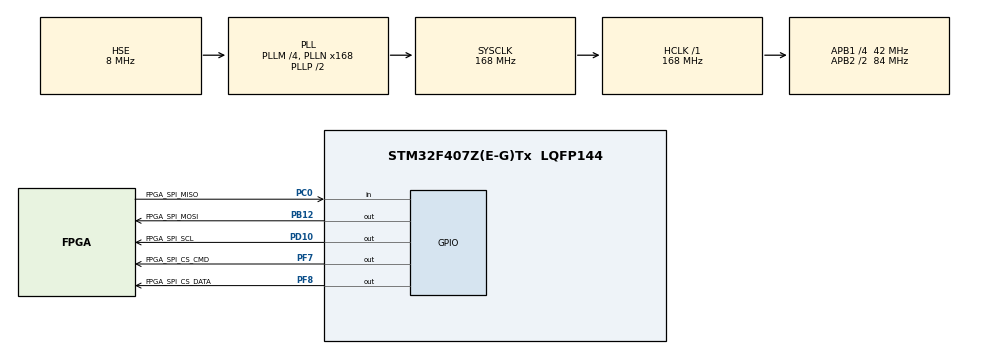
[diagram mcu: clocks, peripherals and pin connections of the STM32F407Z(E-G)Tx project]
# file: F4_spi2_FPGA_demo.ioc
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Mcu.Family=STM32F4
Mcu.Name=STM32F407Z(E-G)Tx
Mcu.Package=LQFP144
NVIC.PriorityGroup=NVIC_PRIORITYGROUP_4
PA13.Mode=Serial_Wire
PA13.Signal=SYS_JTMS-SWDIO
PA14.Mode=Serial_Wire
PA14.Signal=SYS_JTCK-SWCLK
PB12.GPIO_Label=FPGA_SPI_MOSI
PB12.GPIO_Speed=GPIO_SPEED_FREQ_VERY_HIGH
PB12.Signal=GPIO_Output
PC0.GPIO_Label=FPGA_SPI_MISO
PC0.Signal=GPIO_Input
PD10.GPIO_Label=FPGA_SPI_SCL
PD10.GPIO_Speed=GPIO_SPEED_FREQ_VERY_HIGH
PD10.Signal=GPIO_Output
PF7.GPIO_Label=FPGA_SPI_CS_CMD
PF7.GPIO_Speed=GPIO_SPEED_FREQ_VERY_HIGH
PF7.PinState=GPIO_PIN_SET
PF7.Signal=GPIO_Output
PF8.GPIO_Label=FPGA_SPI_CS_DATA
PF8.GPIO_Speed=GPIO_SPEED_FREQ_VERY_HIGH
PF8.PinState=GPIO_PIN_SET
PF8.Signal=GPIO_Output
PH0-OSC_IN.Mode=HSE-External-Oscillator
PH0-OSC_IN.Signal=RCC_OSC_IN
PH1-OSC_OUT.Mode=HSE-External-Oscillator
PH1-OSC_OUT.Signal=RCC_OSC_OUT
ProjectManager.HeapSize=0x200
ProjectManager.StackSize=0x400
ProjectManager.TargetToolchain=MDK-ARM V5.32
RCC.48MHZClocksFreq_Value=84000000
RCC.AHBFreq_Value=168000000
RCC.APB1CLKDivider=RCC_HCLK_DIV4
RCC.APB1Freq_Value=42000000
RCC.APB1TimFreq_Value=84000000
RCC.APB2CLKDivider=RCC_HCLK_DIV2
RCC.APB2Freq_Value=84000000
RCC.APB2TimFreq_Value=168000000
RCC.CortexFreq_Value=168000000
RCC.HCLKFreq_Value=168000000
RCC.HSE_VALUE=8000000
RCC.HSI_VALUE=16000000
RCC.LSE_VALUE=32768
RCC.PLLM=4
RCC.PLLN=168
RCC.PLLSourceVirtual=RCC_PLLSOURCE_HSE
RCC.SYSCLKFreq_VALUE=168000000
RCC.SYSCLKSource=RCC_SYSCLKSOURCE_PLLCLK
RCC.VCOOutputFreq_Value=336000000
TIM6.Prescaler=84-1
VP_TIM6_VS_ClockSourceINT.Mode=Enable_Timer
board=custom

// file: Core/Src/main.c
/* USER CODE BEGIN Header */
/**
  ******************************************************************************
  * @file           : main.c
  * @brief          : Main program body
  ******************************************************************************
  * @attention
  *
  * <h2><center>&copy; Copyright (c) 2021 STMicroelectronics.
  * All rights reserved.</center></h2>
  *
  * This software component is licensed by ST under BSD 3-Clause license,
  * the "License"; You may not use this file except in compliance with the
  * License. You may obtain a copy of the License at:
  *                        opensource.org/licenses/BSD-3-Clause
  *
  ******************************************************************************
  */
/* USER CODE END Header */
#include "main.h"

/* USER CODE BEGIN Includes */
#include "Drv_FPGA_SPI.h"
/* USER CODE END Includes */

TIM_HandleTypeDef htim6;

void SystemClock_Config(void);
static void MX_GPIO_Init(void);
static void MX_TIM6_Init(void);

int main(void)
{

  /* MCU Configuration--------------------------------------------------------*/

  /* Reset of all peripherals, Initializes the Flash interface and the Systick. */
  HAL_Init();

  /* Configure the system clock */
  SystemClock_Config();

  /* Initialize all configured peripherals */
  MX_GPIO_Init();
  MX_TIM6_Init();
  /* USER CODE BEGIN 2 */
  uint32_t i;
	uint32_t buf_send[8] = {0x11, 0x21, 0x32, 0x43, 0x54, 0x65, 0x76, 0x77};
	uint32_t buf_rece[8];
  // todo
		for(i = 0; i < 8; ++i)
		{
			FPGA_SPI_Send(8+i, buf_send[i]);
			HAL_Delay(50);
		}
		HAL_Delay(50);
		for(i = 0; i < 8; ++i)
		{
			buf_rece[i] = FPGA_SPI_Rece(i);
			HAL_Delay(50);
		}
		HAL_Delay(50);
  /* USER CODE END 2 */

  /* Infinite loop */
  /* USER CODE BEGIN WHILE */
  while (1)
  {
//		FPGA_SPI_Send_Cmd(5);

    /* USER CODE END WHILE */

  }
}

void SystemClock_Config(void)
{
  RCC_OscInitTypeDef RCC_OscInitStruct = {0};
  RCC_ClkInitTypeDef RCC_ClkInitStruct = {0};

  /** Configure the main internal regulator output voltage
  */
  __HAL_RCC_PWR_CLK_ENABLE();
  __HAL_PWR_VOLTAGESCALING_CONFIG(PWR_REGULATOR_VOLTAGE_SCALE1);
  /** Initializes the RCC Oscillators according to the specified parameters
  * in the RCC_OscInitTypeDef structure.
  */
  RCC_OscInitStruct.OscillatorType = RCC_OSCILLATORTYPE_HSE;
  RCC_OscInitStruct.HSEState = RCC_HSE_ON;
  RCC_OscInitStruct.PLL.PLLState = RCC_PLL_ON;
  RCC_OscInitStruct.PLL.PLLSource = RCC_PLLSOURCE_HSE;
  RCC_OscInitStruct.PLL.PLLM = 4;
  RCC_OscInitStruct.PLL.PLLN = 168;
  RCC_OscInitStruct.PLL.PLLP = RCC_PLLP_DIV2;
  RCC_OscInitStruct.PLL.PLLQ = 4;
  if (HAL_RCC_OscConfig(&RCC_OscInitStruct) != HAL_OK)
  {
    Error_Handler();
  }
  /** Initializes the CPU, AHB and APB buses clocks
  */
  RCC_ClkInitStruct.ClockType = RCC_CLOCKTYPE_HCLK|RCC_CLOCKTYPE_SYSCLK
                              |RCC_CLOCKTYPE_PCLK1|RCC_CLOCKTYPE_PCLK2;
  RCC_ClkInitStruct.SYSCLKSource = RCC_SYSCLKSOURCE_PLLCLK;
  RCC_ClkInitStruct.AHBCLKDivider = RCC_SYSCLK_DIV1;
  RCC_ClkInitStruct.APB1CLKDivider = RCC_HCLK_DIV4;
  RCC_ClkInitStruct.APB2CLKDivider = RCC_HCLK_DIV2;

  if (HAL_RCC_ClockConfig(&RCC_ClkInitStruct, FLASH_LATENCY_5) != HAL_OK)
  {
    Error_Handler();
  }
}

static void MX_TIM6_Init(void)
{

  TIM_MasterConfigTypeDef sMasterConfig = {0};

  htim6.Instance = TIM6;
  htim6.Init.Prescaler = 84-1;
  htim6.Init.CounterMode = TIM_COUNTERMODE_UP;
  htim6.Init.Period = 65535;
  htim6.Init.AutoReloadPreload = TIM_AUTORELOAD_PRELOAD_DISABLE;
  if (HAL_TIM_Base_Init(&htim6) != HAL_OK)
  {
    Error_Handler();
  }
  sMasterConfig.MasterOutputTrigger = TIM_TRGO_RESET;
  sMasterConfig.MasterSlaveMode = TIM_MASTERSLAVEMODE_DISABLE;
  if (HAL_TIMEx_MasterConfigSynchronization(&htim6, &sMasterConfig) != HAL_OK)
  {
    Error_Handler();
  }

}

static void MX_GPIO_Init(void)
{
  GPIO_InitTypeDef GPIO_InitStruct = {0};

  /* GPIO Ports Clock Enable */
  __HAL_RCC_GPIOE_CLK_ENABLE();
  __HAL_RCC_GPIOC_CLK_ENABLE();
  __HAL_RCC_GPIOF_CLK_ENABLE();
  __HAL_RCC_GPIOH_CLK_ENABLE();
  __HAL_RCC_GPIOA_CLK_ENABLE();
  __HAL_RCC_GPIOB_CLK_ENABLE();
  __HAL_RCC_GPIOG_CLK_ENABLE();
  __HAL_RCC_GPIOD_CLK_ENABLE();

  /*Configure GPIO pin Output Level */
  HAL_GPIO_WritePin(GPIOF, FPGA_SPI_CS_CMD_Pin|FPGA_SPI_CS_DATA_Pin, GPIO_PIN_SET);

  /*Configure GPIO pin Output Level */
  HAL_GPIO_WritePin(FPGA_SPI_MOSI_GPIO_Port, FPGA_SPI_MOSI_Pin, GPIO_PIN_RESET);

  /*Configure GPIO pin Output Level */
  HAL_GPIO_WritePin(FPGA_SPI_SCL_GPIO_Port, FPGA_SPI_SCL_Pin, GPIO_PIN_RESET);

  /*Configure GPIO pins : PE2 PE3 PE4 PE5
                           PE6 PE7 PE8 PE9
                           PE10 PE11 PE12 PE13
                           PE14 PE15 PE0 PE1 */
  GPIO_InitStruct.Pin = GPIO_PIN_2|GPIO_PIN_3|GPIO_PIN_4|GPIO_PIN_5
                          |GPIO_PIN_6|GPIO_PIN_7|GPIO_PIN_8|GPIO_PIN_9
                          |GPIO_PIN_10|GPIO_PIN_11|GPIO_PIN_12|GPIO_PIN_13
                          |GPIO_PIN_14|GPIO_PIN_15|GPIO_PIN_0|GPIO_PIN_1;
  GPIO_InitStruct.Mode = GPIO_MODE_ANALOG;
  GPIO_InitStruct.Pull = GPIO_NOPULL;
  HAL_GPIO_Init(GPIOE, &GPIO_InitStruct);

  /*Configure GPIO pins : PC13 PC14 PC15 PC1
                           PC2 PC3 PC4 PC5
                           PC6 PC7 PC8 PC9
                           PC10 PC11 PC12 */
  GPIO_InitStruct.Pin = GPIO_PIN_13|GPIO_PIN_14|GPIO_PIN_15|GPIO_PIN_1
                          |GPIO_PIN_2|GPIO_PIN_3|GPIO_PIN_4|GPIO_PIN_5
                          |GPIO_PIN_6|GPIO_PIN_7|GPIO_PIN_8|GPIO_PIN_9
                          |GPIO_PIN_10|GPIO_PIN_11|GPIO_PIN_12;
  GPIO_InitStruct.Mode = GPIO_MODE_ANALOG;
  GPIO_InitStruct.Pull = GPIO_NOPULL;
  HAL_GPIO_Init(GPIOC, &GPIO_InitStruct);

  /*Configure GPIO pins : PF0 PF1 PF2 PF3
                           PF4 PF5 PF6 PF9
                           PF10 PF11 PF12 PF13
                           PF14 PF15 */
  GPIO_InitStruct.Pin = GPIO_PIN_0|GPIO_PIN_1|GPIO_PIN_2|GPIO_PIN_3
                          |GPIO_PIN_4|GPIO_PIN_5|GPIO_PIN_6|GPIO_PIN_9
                          |GPIO_PIN_10|GPIO_PIN_11|GPIO_PIN_12|GPIO_PIN_13
                          |GPIO_PIN_14|GPIO_PIN_15;
  GPIO_InitStruct.Mode = GPIO_MODE_ANALOG;
  GPIO_InitStruct.Pull = GPIO_NOPULL;
  HAL_GPIO_Init(GPIOF, &GPIO_InitStruct);

  /*Configure GPIO pins : FPGA_SPI_CS_CMD_Pin FPGA_SPI_CS_DATA_Pin */
  GPIO_InitStruct.Pin = FPGA_SPI_CS_CMD_Pin|FPGA_SPI_CS_DATA_Pin;
  GPIO_InitStruct.Mode = GPIO_MODE_OUTPUT_PP;
  GPIO_InitStruct.Pull = GPIO_NOPULL;
  GPIO_InitStruct.Speed = GPIO_SPEED_FREQ_VERY_HIGH;
  HAL_GPIO_Init(GPIOF, &GPIO_InitStruct);

  /*Configure GPIO pin : FPGA_SPI_MISO_Pin */
  GPIO_InitStruct.Pin = FPGA_SPI_MISO_Pin;
  GPIO_InitStruct.Mode = GPIO_MODE_INPUT;
  GPIO_InitStruct.Pull = GPIO_NOPULL;
  HAL_GPIO_Init(FPGA_SPI_MISO_GPIO_Port, &GPIO_InitStruct);

  /*Configure GPIO pins : PA0 PA1 PA2 PA3
                           PA4 PA5 PA6 PA7
                           PA8 PA9 PA10 PA11
                           PA12 PA15 */
  GPIO_InitStruct.Pin = GPIO_PIN_0|GPIO_PIN_1|GPIO_PIN_2|GPIO_PIN_3
                          |GPIO_PIN_4|GPIO_PIN_5|GPIO_PIN_6|GPIO_PIN_7
                          |GPIO_PIN_8|GPIO_PIN_9|GPIO_PIN_10|GPIO_PIN_11
                          |GPIO_PIN_12|GPIO_PIN_15;
  GPIO_InitStruct.Mode = GPIO_MODE_ANALOG;
  GPIO_InitStruct.Pull = GPIO_NOPULL;
  HAL_GPIO_Init(GPIOA, &GPIO_InitStruct);

  /*Configure GPIO pins : PB0 PB1 PB2 PB10
                           PB11 PB13 PB14 PB15
                           PB3 PB4 PB5 PB6
                           PB7 PB8 PB9 */
  GPIO_InitStruct.Pin = GPIO_PIN_0|GPIO_PIN_1|GPIO_PIN_2|GPIO_PIN_10
                          |GPIO_PIN_11|GPIO_PIN_13|GPIO_PIN_14|GPIO_PIN_15
                          |GPIO_PIN_3|GPIO_PIN_4|GPIO_PIN_5|GPIO_PIN_6
                          |GPIO_PIN_7|GPIO_PIN_8|GPIO_PIN_9;
  GPIO_InitStruct.Mode = GPIO_MODE_ANALOG;
  GPIO_InitStruct.Pull = GPIO_NOPULL;
  HAL_GPIO_Init(GPIOB, &GPIO_InitStruct);

  /*Configure GPIO pins : PG0 PG1 PG2 PG3
                           PG4 PG5 PG6 PG7
                           PG8 PG9 PG10 PG11
                           PG12 PG13 PG14 PG15 */
  GPIO_InitStruct.Pin = GPIO_PIN_0|GPIO_PIN_1|GPIO_PIN_2|GPIO_PIN_3
                          |GPIO_PIN_4|GPIO_PIN_5|GPIO_PIN_6|GPIO_PIN_7
                          |GPIO_PIN_8|GPIO_PIN_9|GPIO_PIN_10|GPIO_PIN_11
                          |GPIO_PIN_12|GPIO_PIN_13|GPIO_PIN_14|GPIO_PIN_15;
  GPIO_InitStruct.Mode = GPIO_MODE_ANALOG;
  GPIO_InitStruct.Pull = GPIO_NOPULL;
  HAL_GPIO_Init(GPIOG, &GPIO_InitStruct);

  /*Configure GPIO pin : FPGA_SPI_MOSI_Pin */
  GPIO_InitStruct.Pin = FPGA_SPI_MOSI_Pin;
  GPIO_InitStruct.Mode = GPIO_MODE_OUTPUT_PP;
  GPIO_InitStruct.Pull = GPIO_NOPULL;
  GPIO_InitStruct.Speed = GPIO_SPEED_FREQ_VERY_HIGH;
  HAL_GPIO_Init(FPGA_SPI_MOSI_GPIO_Port, &GPIO_InitStruct);

  /*Configure GPIO pins : PD8 PD9 PD11 PD12
                           PD13 PD14 PD15 PD0
                           PD1 PD2 PD3 PD4
                           PD5 PD6 PD7 */
  GPIO_InitStruct.Pin = GPIO_PIN_8|GPIO_PIN_9|GPIO_PIN_11|GPIO_PIN_12
                          |GPIO_PIN_13|GPIO_PIN_14|GPIO_PIN_15|GPIO_PIN_0
                          |GPIO_PIN_1|GPIO_PIN_2|GPIO_PIN_3|GPIO_PIN_4
                          |GPIO_PIN_5|GPIO_PIN_6|GPIO_PIN_7;
  GPIO_InitStruct.Mode = GPIO_MODE_ANALOG;
  GPIO_InitStruct.Pull = GPIO_NOPULL;
  HAL_GPIO_Init(GPIOD, &GPIO_InitStruct);

  /*Configure GPIO pin : FPGA_SPI_SCL_Pin */
  GPIO_InitStruct.Pin = FPGA_SPI_SCL_Pin;
  GPIO_InitStruct.Mode = GPIO_MODE_OUTPUT_PP;
  GPIO_InitStruct.Pull = GPIO_NOPULL;
  GPIO_InitStruct.Speed = GPIO_SPEED_FREQ_VERY_HIGH;
  HAL_GPIO_Init(FPGA_SPI_SCL_GPIO_Port, &GPIO_InitStruct);

}

void Error_Handler(void)
{
  __disable_irq();
  while (1)
  {
  }
}

/************************ (C) COPYRIGHT STMicroelectronics *****END OF FILE****/
